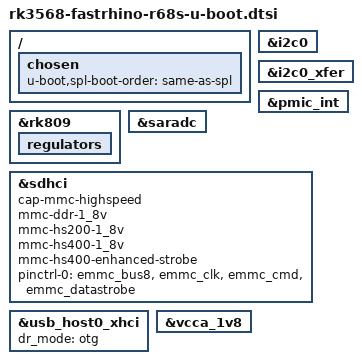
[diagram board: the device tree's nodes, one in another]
// SPDX-License-Identifier: GPL-2.0-or-later OR MIT

#include "rk3568-fastrhino-r66s-u-boot.dtsi"

/ {
	chosen {
		u-boot,spl-boot-order = "same-as-spl", &sdhci;
	};
};

&i2c0 {
	bootph-pre-ram;
};

&i2c0_xfer {
	bootph-pre-ram;
};

&pmic_int {
	bootph-pre-ram;
};

&rk809 {
	bootph-pre-ram;

	regulators {
		bootph-pre-ram;
	};
};

&saradc {
	bootph-pre-ram;
};

&sdhci {
	cap-mmc-highspeed;
	mmc-ddr-1_8v;
	mmc-hs200-1_8v;
	mmc-hs400-1_8v;
	mmc-hs400-enhanced-strobe;
	pinctrl-0 = <&emmc_bus8 &emmc_clk &emmc_cmd &emmc_datastrobe>;
};

&usb_host0_xhci {
	dr_mode = "otg";
};

&vcca_1v8 {
	bootph-pre-ram;
};
